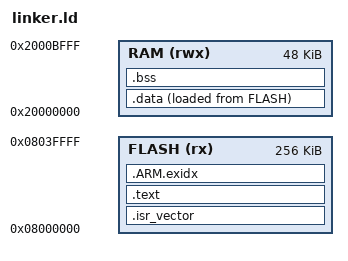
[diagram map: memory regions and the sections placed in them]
/* STM32F103RCT6 high-density: 256 KB Flash, 48 KB SRAM */

MEMORY
{
    FLASH (rx)  : ORIGIN = 0x08000000, LENGTH = 256K
    RAM   (rwx) : ORIGIN = 0x20000000, LENGTH = 48K
}

_estack = ORIGIN(RAM) + LENGTH(RAM);

SECTIONS
{
    .isr_vector :
    {
        KEEP(*(.isr_vector))
    } > FLASH

    .text :
    {
        *(.text*)
        *(.rodata*)
        KEEP(*(.init))
        KEEP(*(.fini))
    } > FLASH

    .ARM.exidx :
    {
        *(.ARM.exidx*)
    } > FLASH

    .data :
    {
        _sidata = LOADADDR(.data);
        _sdata = .;
        *(.data*)
        _edata = .;
    } > RAM AT > FLASH

    .bss :
    {
        _sbss = .;
        *(.bss*)
        *(COMMON)
        _ebss = .;
    } > RAM

    _end = .;
}
